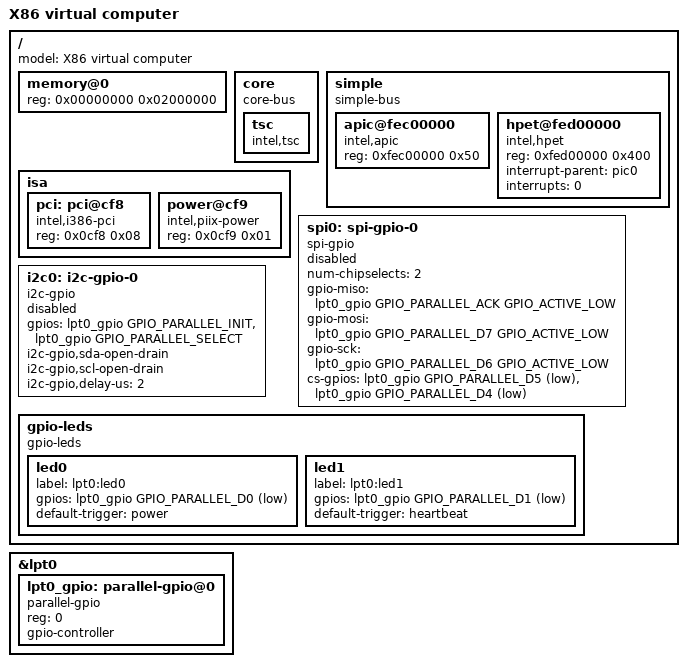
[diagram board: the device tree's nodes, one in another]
/* SPDX-License-Identifier: GPL-2.0-or-later */
/*
 * Copyright(c) 2022 Sanpe <sanpeqf@gmail.com>
 */

/dts-v1/;

#include "ibmpc.dtsi"
#include <dt-bindings/gpio.h>
#include <dt-bindings/gpio/parallel.h>

/ {
    model = "X86 virtual computer";

    memory@0 {
        device_type = "memory";
        reg = <0x00000000 0x02000000>;
    };

    core {
        compatible = "core-bus";
        tsc {
            compatible = "intel,tsc";
        };
    };

    simple {
        #address-cells = <1>;
        #size-cells = <1>;
        compatible = "simple-bus";

        apic@fec00000 {
            compatible = "intel,apic";
            reg = <0xfec00000 0x50>;
        };

        hpet@fed00000 {
            compatible = "intel,hpet";
            reg = <0xfed00000 0x400>;
            interrupt-parent = <&pic0>;
            interrupts = <0>;
        };
    };

    isa {
        pci: pci@cf8 {
            compatible = "intel,i386-pci";
            reg = <0x0cf8 0x08>;
        };

        power@cf9 {
            compatible = "intel,piix-power";
            reg = <0x0cf9 0x01>;
        };
    };

    spi0: spi-gpio-0 {
        compatible = "spi-gpio";
        num-chipselects = <2>;
        gpio-miso = <&lpt0_gpio GPIO_PARALLEL_ACK GPIO_ACTIVE_LOW>;
        gpio-mosi = <&lpt0_gpio GPIO_PARALLEL_D7 GPIO_ACTIVE_LOW>;
        gpio-sck = <&lpt0_gpio GPIO_PARALLEL_D6 GPIO_ACTIVE_LOW>;
        cs-gpios = <&lpt0_gpio GPIO_PARALLEL_D5 GPIO_ACTIVE_LOW>,
                   <&lpt0_gpio GPIO_PARALLEL_D4 GPIO_ACTIVE_LOW>;
        #address-cells = <1>;
        #size-cells = <0>;
        status = "disabled";
    };

    i2c0: i2c-gpio-0 {
        compatible = "i2c-gpio";
        gpios = <&lpt0_gpio GPIO_PARALLEL_INIT GPIO_ACTIVE_HIGH>,
                <&lpt0_gpio GPIO_PARALLEL_SELECT GPIO_ACTIVE_HIGH>;
        i2c-gpio,sda-open-drain;
        i2c-gpio,scl-open-drain;
        i2c-gpio,delay-us = <2>;
        #address-cells = <1>;
        #size-cells = <0>;
        status = "disabled";
    };

    gpio-leds {
		compatible = "gpio-leds";
        led0 {
            label = "lpt0:led0";
            gpios = <&lpt0_gpio GPIO_PARALLEL_D0 GPIO_ACTIVE_LOW>;
            default-trigger = "power";
        };
        led1 {
            label = "lpt0:led1";
            gpios = <&lpt0_gpio GPIO_PARALLEL_D1 GPIO_ACTIVE_LOW>;
            default-trigger = "heartbeat";
        };
    };
};

&lpt0 {
    lpt0_gpio: parallel-gpio@0 {
        compatible = "parallel-gpio";
        reg = <0>;
        gpio-controller;
        #gpio-cells = <2>;
    };
};
